# jbr_MDR1986VE1T register map
Registers are 32-bit, access not given, no defined reset value unless marked. A register's access mark holds for its fields unless they carry their own. Addresses are absolute; registers are grouped by the start of their names; [hi:lo] are bit positions; {n}, {i} and the like mark numbered series.

## GPIOD
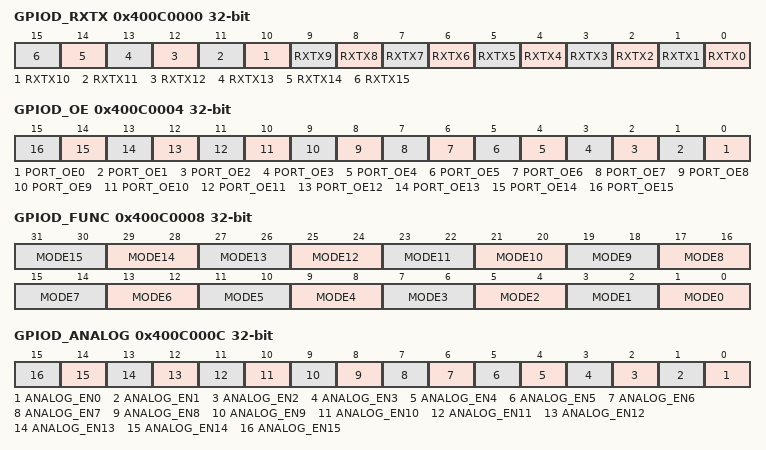
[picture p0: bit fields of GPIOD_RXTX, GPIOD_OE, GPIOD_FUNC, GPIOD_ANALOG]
0x400C0000 GPIOD_RXTX
  [n] RXTX{n} (n=0..15)
0x400C0004 GPIOD_OE
  [n] PORT_OE{n} (n=0..15)
0x400C0008 GPIOD_FUNC
  [2n+1:2n] MODE{n} (n=0..15)
0x400C000C GPIOD_ANALOG
  [n] ANALOG_EN{n} (n=0..15)
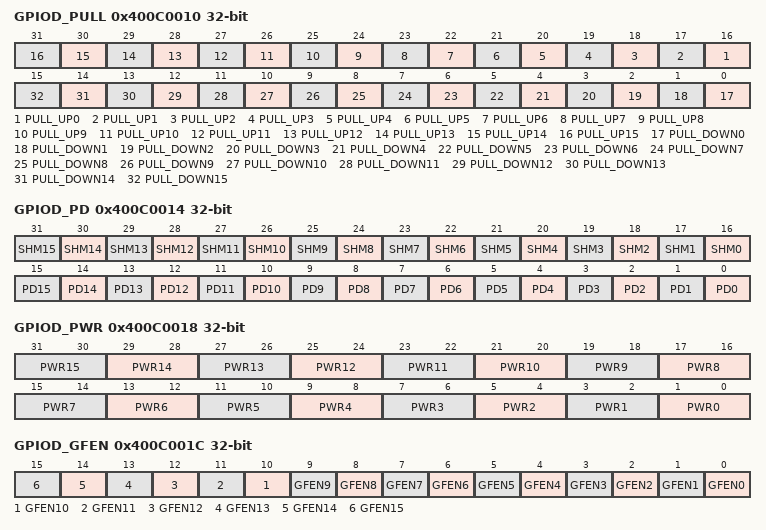
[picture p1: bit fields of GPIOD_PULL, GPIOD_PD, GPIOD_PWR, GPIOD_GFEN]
0x400C0010 GPIOD_PULL
  [n+16] PULL_UP{n} (n=0..15), [n] PULL_DOWN{n} (n=0..15)
0x400C0014 GPIOD_PD
  [n+16] SHM{n} (n=0..15), [n] PD{n} (n=0..15)
0x400C0018 GPIOD_PWR
  [2n+1:2n] PWR{n} (n=0..15)
0x400C001C GPIOD_GFEN
  [n] GFEN{n} (n=0..15)
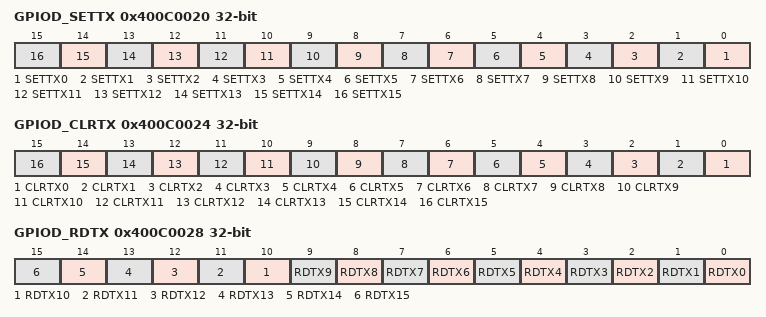
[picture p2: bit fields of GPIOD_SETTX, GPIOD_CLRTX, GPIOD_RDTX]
0x400C0020 GPIOD_SETTX
  [n] SETTX{n} (n=0..15)
0x400C0024 GPIOD_CLRTX
  [n] CLRTX{n} (n=0..15)
0x400C0028 GPIOD_RDTX
  [n] RDTX{n} (n=0..15)

## GPIOE
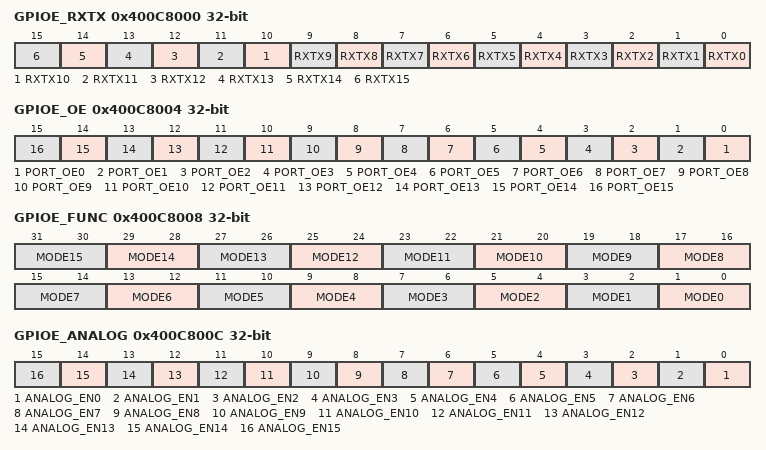
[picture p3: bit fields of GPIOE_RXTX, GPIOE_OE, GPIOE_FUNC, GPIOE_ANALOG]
0x400C8000 GPIOE_RXTX
  [n] RXTX{n} (n=0..15)
0x400C8004 GPIOE_OE
  [n] PORT_OE{n} (n=0..15)
0x400C8008 GPIOE_FUNC
  [2n+1:2n] MODE{n} (n=0..15)
0x400C800C GPIOE_ANALOG
  [n] ANALOG_EN{n} (n=0..15)
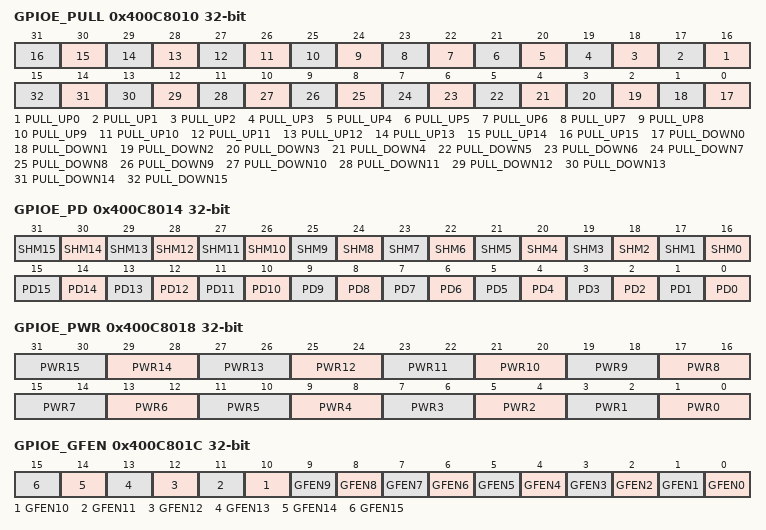
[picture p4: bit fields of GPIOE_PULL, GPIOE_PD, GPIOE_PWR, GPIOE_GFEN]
0x400C8010 GPIOE_PULL
  [n+16] PULL_UP{n} (n=0..15), [n] PULL_DOWN{n} (n=0..15)
0x400C8014 GPIOE_PD
  [n+16] SHM{n} (n=0..15), [n] PD{n} (n=0..15)
0x400C8018 GPIOE_PWR
  [2n+1:2n] PWR{n} (n=0..15)
0x400C801C GPIOE_GFEN
  [n] GFEN{n} (n=0..15)
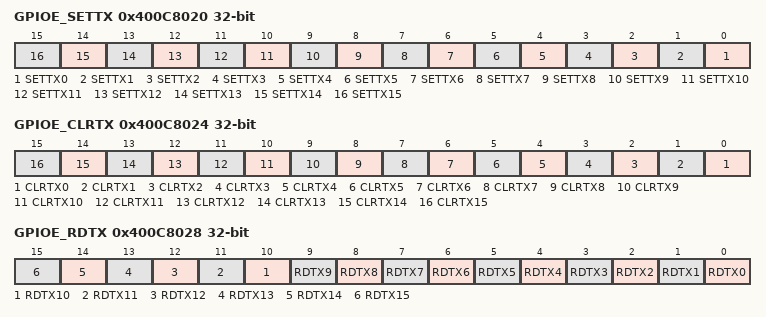
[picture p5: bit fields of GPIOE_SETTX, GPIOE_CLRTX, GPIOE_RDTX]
0x400C8020 GPIOE_SETTX
  [n] SETTX{n} (n=0..15)
0x400C8024 GPIOE_CLRTX
  [n] CLRTX{n} (n=0..15)
0x400C8028 GPIOE_RDTX
  [n] RDTX{n} (n=0..15)

## GPIOF
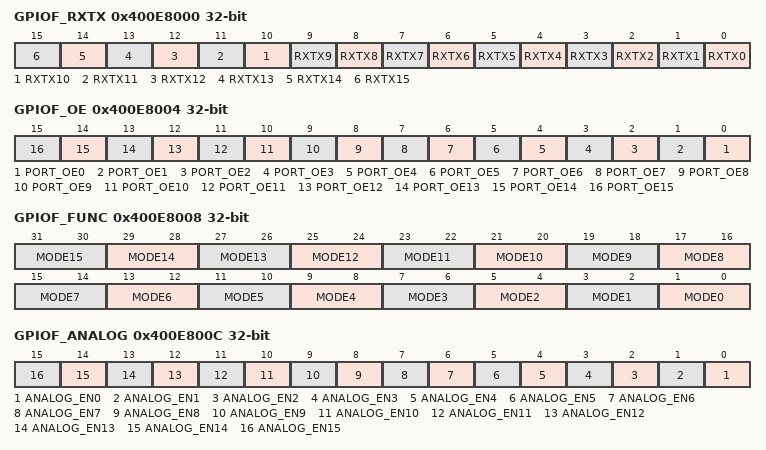
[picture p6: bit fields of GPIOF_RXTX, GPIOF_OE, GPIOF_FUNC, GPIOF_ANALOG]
0x400E8000 GPIOF_RXTX
  [n] RXTX{n} (n=0..15)
0x400E8004 GPIOF_OE
  [n] PORT_OE{n} (n=0..15)
0x400E8008 GPIOF_FUNC
  [2n+1:2n] MODE{n} (n=0..15)
0x400E800C GPIOF_ANALOG
  [n] ANALOG_EN{n} (n=0..15)
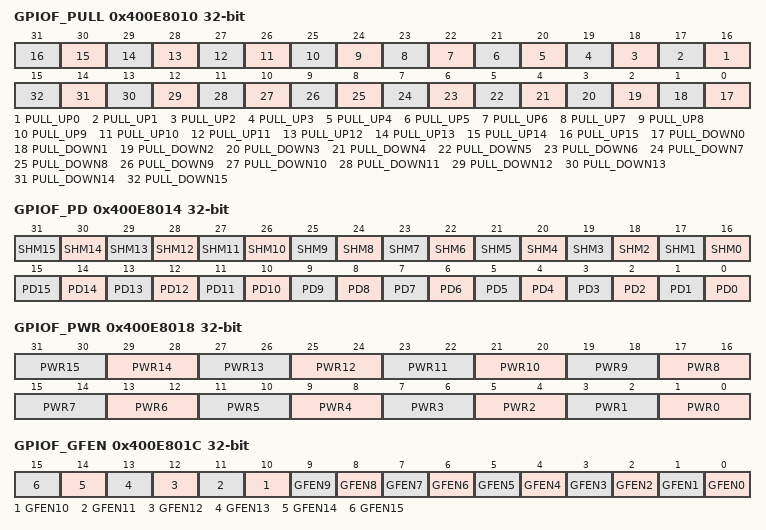
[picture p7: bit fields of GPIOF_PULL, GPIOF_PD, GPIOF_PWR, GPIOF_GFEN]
0x400E8010 GPIOF_PULL
  [n+16] PULL_UP{n} (n=0..15), [n] PULL_DOWN{n} (n=0..15)
0x400E8014 GPIOF_PD
  [n+16] SHM{n} (n=0..15), [n] PD{n} (n=0..15)
0x400E8018 GPIOF_PWR
  [2n+1:2n] PWR{n} (n=0..15)
0x400E801C GPIOF_GFEN
  [n] GFEN{n} (n=0..15)
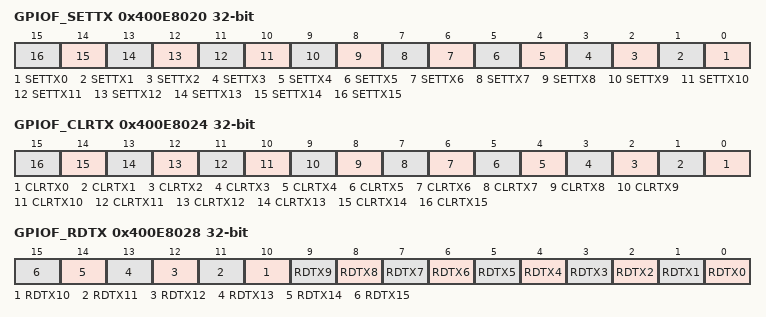
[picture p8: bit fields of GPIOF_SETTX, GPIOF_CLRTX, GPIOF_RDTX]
0x400E8020 GPIOF_SETTX
  [n] SETTX{n} (n=0..15)
0x400E8024 GPIOF_CLRTX
  [n] CLRTX{n} (n=0..15)
0x400E8028 GPIOF_RDTX
  [n] RDTX{n} (n=0..15)

## DMA
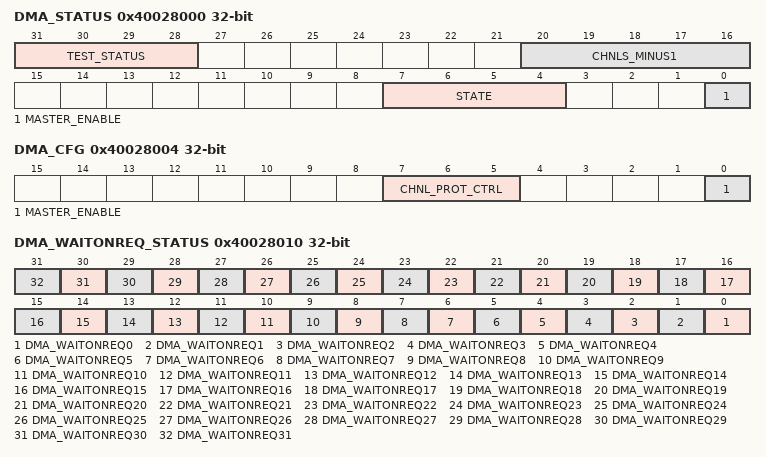
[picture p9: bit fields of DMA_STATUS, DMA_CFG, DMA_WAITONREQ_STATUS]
0x40028000 DMA_STATUS
  [31:28] TEST_STATUS, [20:16] CHNLS_MINUS1, [7:4] STATE, [0] MASTER_ENABLE
0x40028004 DMA_CFG
  [7:5] CHNL_PROT_CTRL, [0] MASTER_ENABLE
0x40028010 DMA_WAITONREQ_STATUS
  [n] DMA_WAITONREQ{n} (n=0..31)

## CHNL
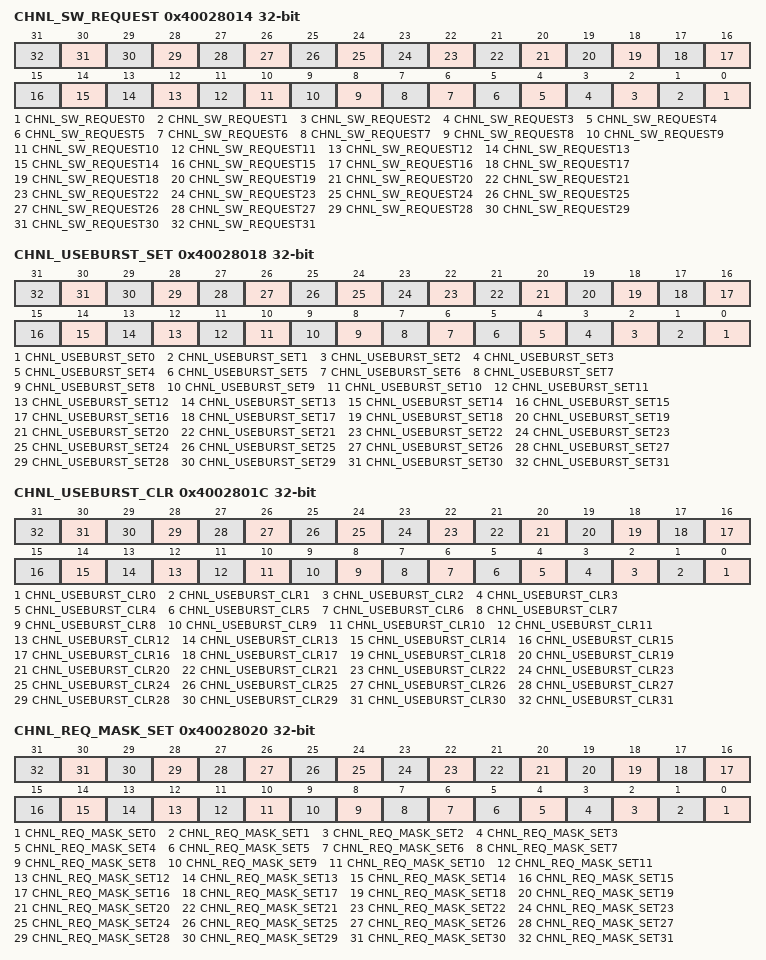
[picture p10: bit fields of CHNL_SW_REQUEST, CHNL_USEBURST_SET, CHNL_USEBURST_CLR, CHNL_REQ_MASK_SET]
0x40028014 CHNL_SW_REQUEST
  [n] CHNL_SW_REQUEST{n} (n=0..31)
0x40028018 CHNL_USEBURST_SET
  [n] CHNL_USEBURST_SET{n} (n=0..31)
0x4002801C CHNL_USEBURST_CLR
  [n] CHNL_USEBURST_CLR{n} (n=0..31)
0x40028020 CHNL_REQ_MASK_SET
  [n] CHNL_REQ_MASK_SET{n} (n=0..31)
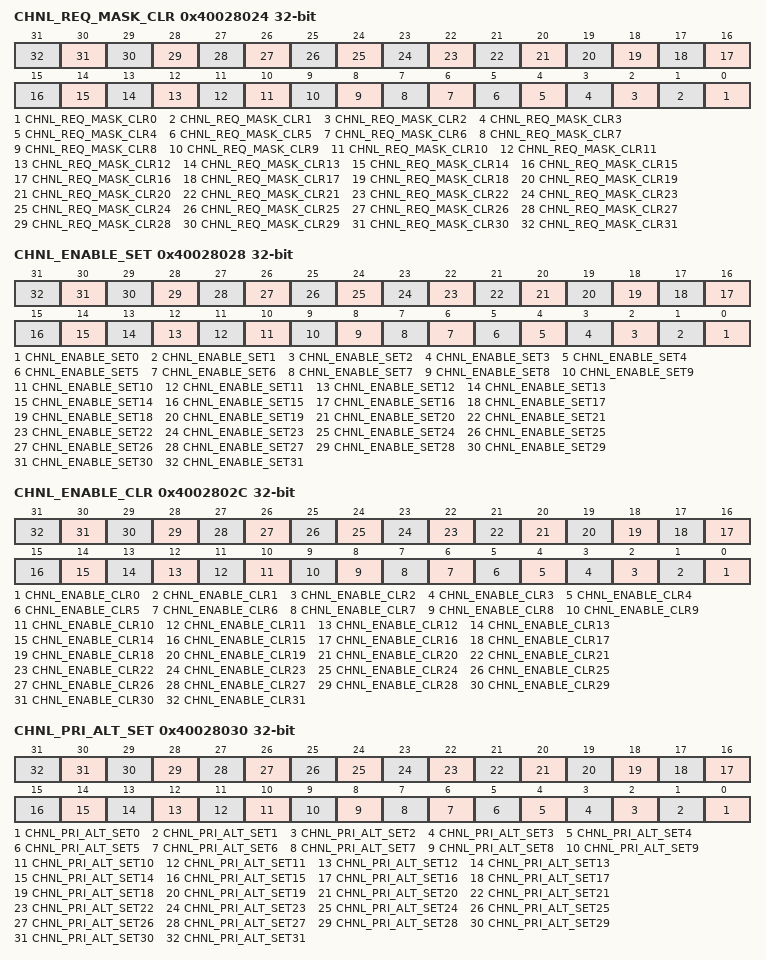
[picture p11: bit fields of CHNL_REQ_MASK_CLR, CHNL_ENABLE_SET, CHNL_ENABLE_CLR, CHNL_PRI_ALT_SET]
0x40028024 CHNL_REQ_MASK_CLR
  [n] CHNL_REQ_MASK_CLR{n} (n=0..31)
0x40028028 CHNL_ENABLE_SET
  [n] CHNL_ENABLE_SET{n} (n=0..31)
0x4002802C CHNL_ENABLE_CLR
  [n] CHNL_ENABLE_CLR{n} (n=0..31)
0x40028030 CHNL_PRI_ALT_SET
  [n] CHNL_PRI_ALT_SET{n} (n=0..31)
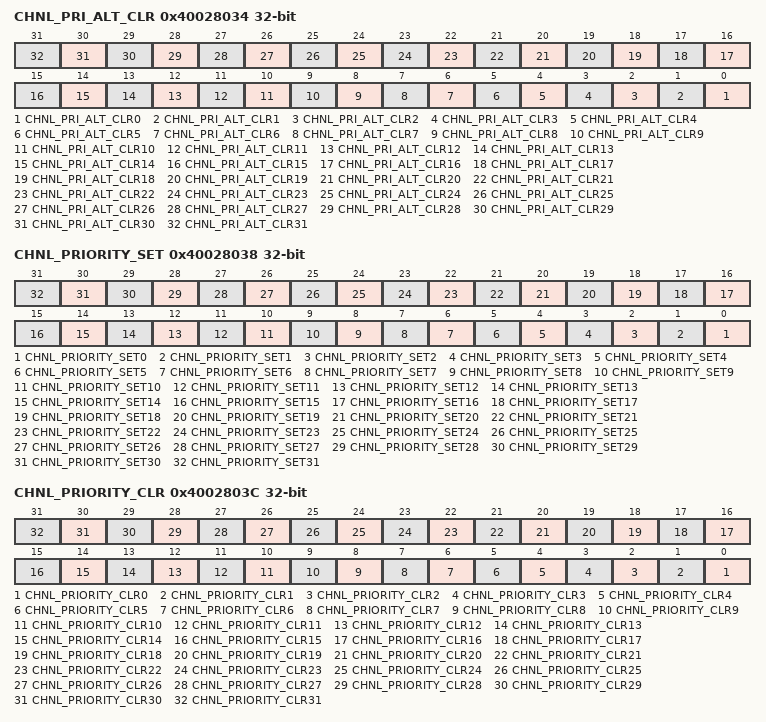
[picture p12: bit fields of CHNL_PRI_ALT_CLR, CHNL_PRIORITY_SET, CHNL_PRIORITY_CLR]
0x40028034 CHNL_PRI_ALT_CLR
  [n] CHNL_PRI_ALT_CLR{n} (n=0..31)
0x40028038 CHNL_PRIORITY_SET
  [n] CHNL_PRIORITY_SET{n} (n=0..31)
0x4002803C CHNL_PRIORITY_CLR
  [n] CHNL_PRIORITY_CLR{n} (n=0..31)

## IWDG
0x40068000 IWDG_KR 16-bit
  [15:0] KEY
0x40068004 IWDG_PR 16-bit
  [2:0] PR
0x40068008 IWDG_RLR 16-bit
  [11:0] RLR
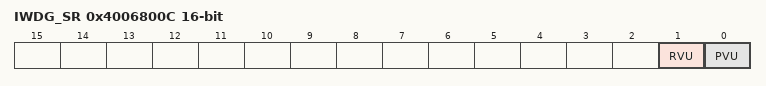
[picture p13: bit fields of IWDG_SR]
0x4006800C IWDG_SR 16-bit
  [1] RVU, [0] PVU

## WWDG
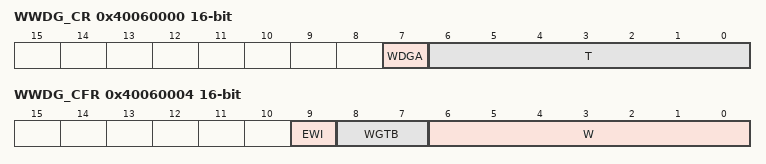
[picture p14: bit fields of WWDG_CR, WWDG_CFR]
0x40060000 WWDG_CR 16-bit
  [7] WDGA, [6:0] T
0x40060004 WWDG_CFR 16-bit
  [9] EWI, [8:7] WGTB, [6:0] W
0x40060008 WWDG_SR 16-bit
  [0] EWIF

## I2C
0x40050000 I2C_PRL
  [7:0] PR
0x40050004 I2C_PRH
  [7:0] PR
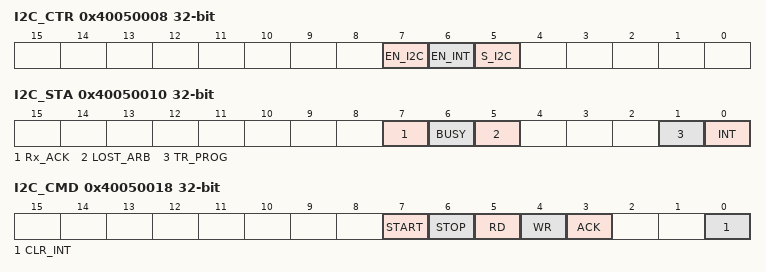
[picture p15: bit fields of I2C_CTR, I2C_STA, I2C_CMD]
0x40050008 I2C_CTR
  [7] EN_I2C, [6] EN_INT, [5] S_I2C
0x4005000C I2C_RXD
  [7:0] RXD
0x40050010 I2C_STA
  [7] Rx_ACK, [6] BUSY, [5] LOST_ARB, [1] TR_PROG, [0] INT
0x40050014 I2C_TXD
  [7:0] TXD
0x40050018 I2C_CMD
  [7] START, [6] STOP, [5] RD, [4] WR, [3] ACK, [0] CLR_INT

## SSP1
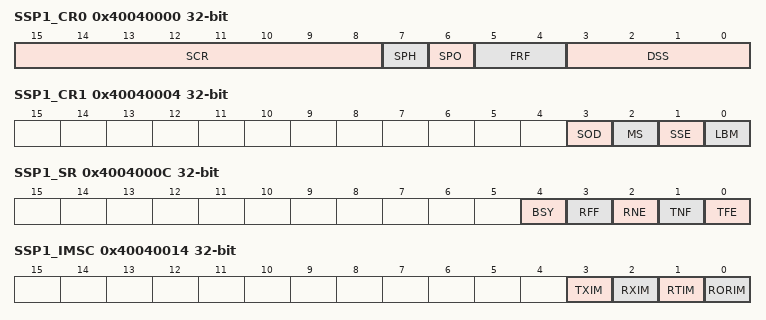
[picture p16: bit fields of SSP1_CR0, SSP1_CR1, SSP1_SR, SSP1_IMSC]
0x40040000 SSP1_CR0
  [15:8] SCR, [7] SPH, [6] SPO, [5:4] FRF, [3:0] DSS
0x40040004 SSP1_CR1
  [3] SOD, [2] MS, [1] SSE, [0] LBM
0x40040008 SSP1_DR
  [15:0] DATA
0x4004000C SSP1_SR
  [4] BSY, [3] RFF, [2] RNE, [1] TNF, [0] TFE
0x40040010 SSP1_CPSR
  [7:0] CPSDVSR
0x40040014 SSP1_IMSC
  [3] TXIM, [2] RXIM, [1] RTIM, [0] RORIM
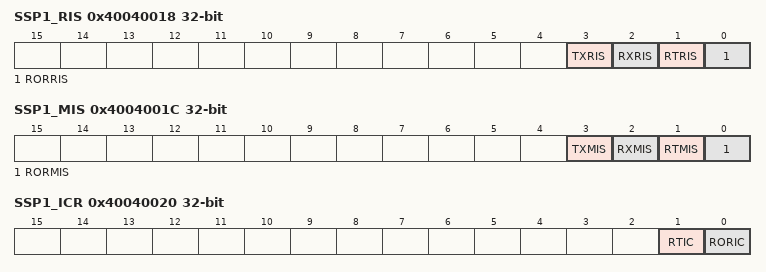
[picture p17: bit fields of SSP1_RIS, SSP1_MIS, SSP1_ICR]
0x40040018 SSP1_RIS
  [3] TXRIS, [2] RXRIS, [1] RTRIS, [0] RORRIS
0x4004001C SSP1_MIS
  [3] TXMIS, [2] RXMIS, [1] RTMIS, [0] RORMIS
0x40040020 SSP1_ICR
  [1] RTIC, [0] RORIC
0x40040024 SSP1_DMACR
  [1] TXDMAE, [0] RXDMAE
